VERSION ""

NS_ :

BS_:

BU_: Gateway_Front Gateway_Rear ECU BMS GI_Left GI_Right Dashboard Telemetry IMU LV_SOC Programming

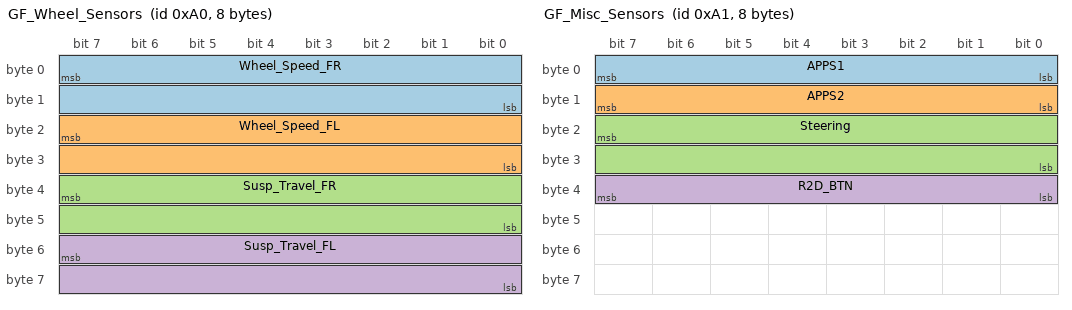
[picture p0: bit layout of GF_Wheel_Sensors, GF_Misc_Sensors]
BO_ 160 GF_Wheel_Sensors: 8 Gateway_Front
 SG_ Wheel_Speed_FR : 7|16@0+ (1.0,0) [0.0|8000.0] "rpm" Telemetry,GI_Left,GI_Right
 SG_ Wheel_Speed_FL : 23|16@0+ (1.0,0) [0.0|8000.0] "rpm" Telemetry,GI_Left,GI_Right
 SG_ Susp_Travel_FR : 39|16@0+ (0.001,0) [0.0|65.535] "mm" Telemetry,GI_Left,GI_Right
 SG_ Susp_Travel_FL : 55|16@0+ (0.001,0) [0.0|65.535] "mm" Telemetry,GI_Left,GI_Right
BO_ 161 GF_Misc_Sensors: 8 Gateway_Front
 SG_ APPS1 : 7|8@0+ (1.0,0) [0.0|100.0] "%" Telemetry,GI_Left,GI_Right,ECU
 SG_ APPS2 : 15|8@0+ (1.0,0) [0.0|100.0] "%" Telemetry,GI_Left,GI_Right,ECU
 SG_ Steering : 23|16@0- (0.01,0) [-290.0|290.0] "deg" Telemetry,GI_Left,GI_Right,ECU
 SG_ R2D_BTN : 39|8@0+ (1.0,0) [0.0|1.0] "bool" Telemetry,GI_Left,GI_Right,ECU
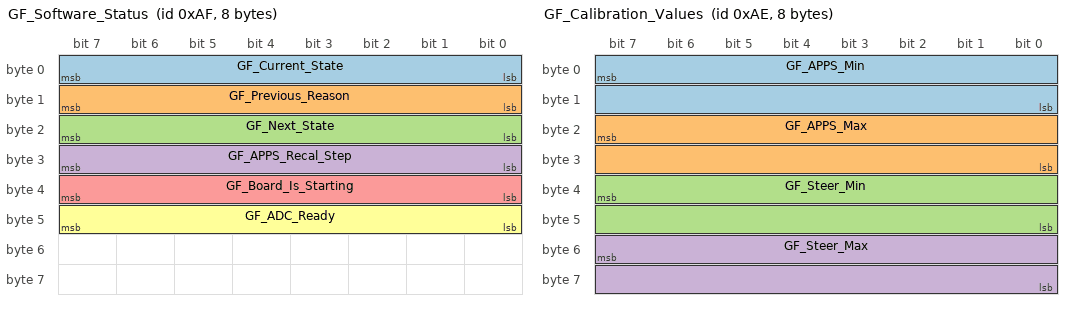
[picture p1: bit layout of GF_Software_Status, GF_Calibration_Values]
BO_ 175 GF_Software_Status: 8 Gateway_Front
 SG_ GF_Current_State : 7|8@0+ (1.0,0) [0.0|255.0] "hex" Telemetry
 SG_ GF_Previous_Reason : 15|8@0+ (1.0,0) [0.0|255.0] "hex" Telemetry
 SG_ GF_Next_State : 23|8@0+ (1.0,0) [0.0|255.0] "hex" Telemetry
 SG_ GF_APPS_Recal_Step : 31|8@0+ (1.0,0) [0.0|3.0] "hex" Telemetry
 SG_ GF_Board_Is_Starting : 39|8@0+ (1.0,0) [0.0|1.0] "bool" Telemetry
 SG_ GF_ADC_Ready : 47|8@0+ (1.0,0) [0.0|1.0] "bool" Telemetry
BO_ 174 GF_Calibration_Values: 8 Gateway_Front
 SG_ GF_APPS_Min : 7|16@0+ (1.0,0) [0.0|65535.0] "dec" Telemetry,Dashboard
 SG_ GF_APPS_Max : 23|16@0+ (1.0,0) [0.0|65535.0] "dec" Telemetry,Dashboard
 SG_ GF_Steer_Min : 39|16@0+ (1.0,0) [0.0|65535.0] "dec" Telemetry,Dashboard
 SG_ GF_Steer_Max : 55|16@0+ (1.0,0) [0.0|65535.0] "dec" Telemetry,Dashboard

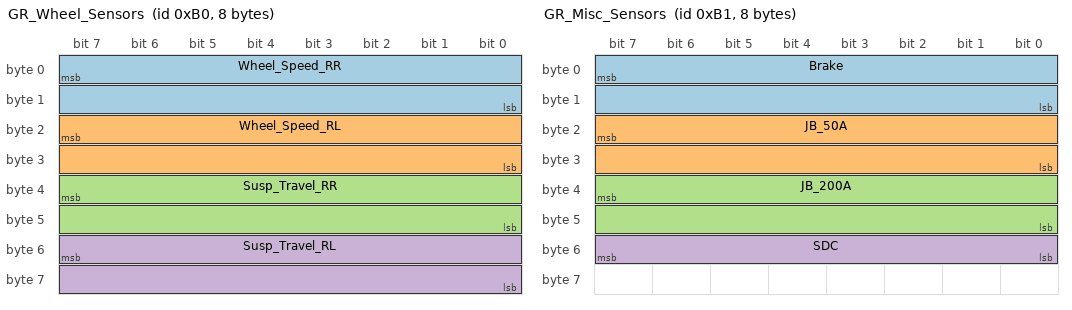
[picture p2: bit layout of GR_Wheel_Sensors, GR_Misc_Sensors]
BO_ 176 GR_Wheel_Sensors: 8 Gateway_Rear
 SG_ Wheel_Speed_RR : 7|16@0+ (1.0,0) [0.0|8000.0] "rpm" Telemetry,GIs
 SG_ Wheel_Speed_RL : 23|16@0+ (1.0,0) [0.0|8000.0] "rpm" Telemetry,GIs
 SG_ Susp_Travel_RR : 39|16@0+ (0.001,0) [0.0|65.535] "mm" Telemetry,GIs
 SG_ Susp_Travel_RL : 55|16@0+ (0.001,0) [0.0|65.535] "mm" Telemetry,GIs
BO_ 177 GR_Misc_Sensors: 8 Gateway_Rear
 SG_ Brake : 7|16@0+ (0.01,0) [0.0|100.0] "bar" Telemetry,GI_Left,GI_Right,ECU
 SG_ JB_50A : 23|16@0- (0.01,0) [-70.0|70.0] "A" Telemetry,GI_Left,GI_Right,ECU
 SG_ JB_200A : 39|16@0- (0.01,0) [-300.0|300.0] "A" Telemetry,GI_Left,GI_Right,ECU
 SG_ SDC : 55|8@0+ (1.0,0) [0.0|1.0] "Bool" Telemetry,GI_Left,GI_Right,ECU
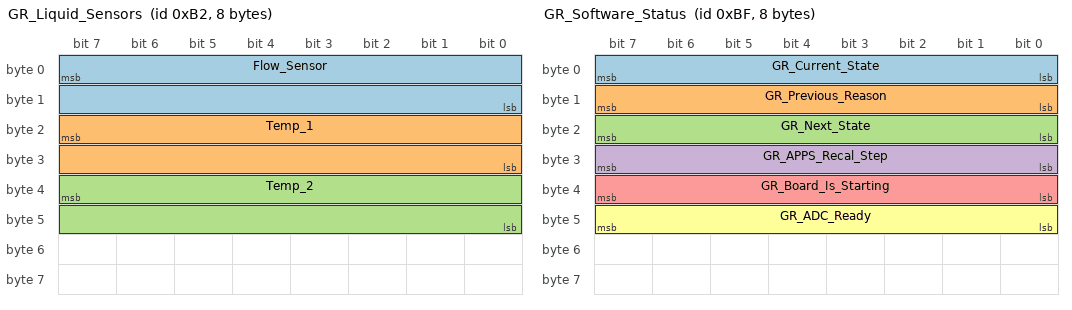
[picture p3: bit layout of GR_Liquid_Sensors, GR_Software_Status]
BO_ 178 GR_Liquid_Sensors: 8 Gateway_Rear
 SG_ Flow_Sensor : 7|16@0+ (1.0,0) [0.0|100.0] "L/m" ECU,Telemetry
 SG_ Temp_1 : 23|16@0- (0.001,0) [-10.0|100.0] "degC" ECU,Telemetry
 SG_ Temp_2 : 39|16@0- (0.001,0) [-10.0|100.0] "degC" ECU,Telemetry
BO_ 191 GR_Software_Status: 8 Gateway_Rear
 SG_ GR_Current_State : 7|8@0+ (1.0,0) [0.0|255.0] "hex" Telemetry
 SG_ GR_Previous_Reason : 15|8@0+ (1.0,0) [0.0|255.0] "hex" Telemetry
 SG_ GR_Next_State : 23|8@0+ (1.0,0) [0.0|255.0] "hex" Telemetry
 SG_ GR_APPS_Recal_Step : 31|8@0+ (1.0,0) [0.0|3.0] "hex" Telemetry
 SG_ GR_Board_Is_Starting : 39|8@0+ (1.0,0) [0.0|1.0] "bool" Telemetry
 SG_ GR_ADC_Ready : 47|8@0+ (1.0,0) [0.0|1.0] "bool" Telemetry

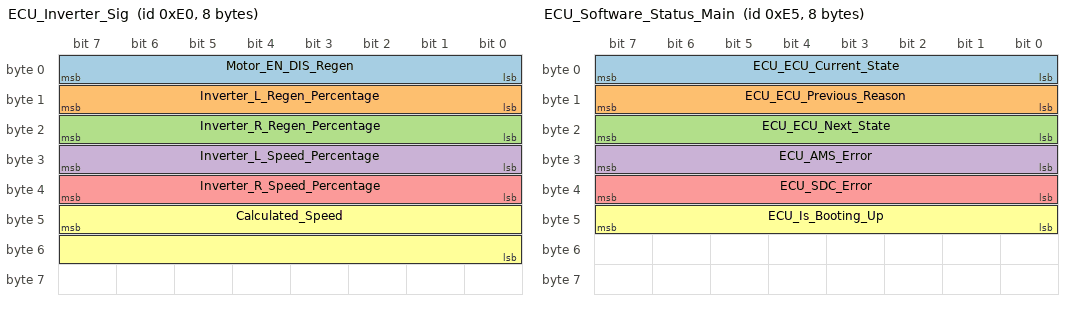
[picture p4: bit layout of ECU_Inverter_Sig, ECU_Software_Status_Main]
BO_ 224 ECU_Inverter_Sig: 8 ECU
 SG_ Motor_EN_DIS_Regen : 7|8@0+ (1.0,0) [0.0|2.0] "enum" Telemetry,GI_Left,GI_Right
 SG_ Inverter_L_Regen_Percentage : 15|8@0+ (1.0,0) [0.0|100.0] "%" Telemetry,GI_Left,GI_Right
 SG_ Inverter_R_Regen_Percentage : 23|8@0+ (1.0,0) [0.0|100.0] "%" Telemetry,GI_Left,GI_Right
 SG_ Inverter_L_Speed_Percentage : 31|8@0+ (1.0,0) [0.0|100.0] "%" Telemetry,GI_Left,GI_Right
 SG_ Inverter_R_Speed_Percentage : 39|8@0+ (1.0,0) [0.0|100.0] "%" Telemetry,GI_Left,GI_Right
 SG_ Calculated_Speed : 47|16@0+ (0.01,0) [0.0|200.0] "km/h" Telemetry,GI_Left,GI_Right
BO_ 179 ECU_Rear_NMOS: 8 ECU
 SG_ R2D_Buzzer_On_Off : 7|8@0+ (1.0,0) [0.0|1.0] "bool" Telemetry,Gateway_Rear
BO_ 162 ECU_Front_NMOS: 8 ECU
 SG_ R2D_LED_Delay : 7|8@0+ (1.0,0) [0.0|255.0] "Hz" Telemetry,Gateway_Front
BO_ 229 ECU_Software_Status_Main: 8 ECU
 SG_ ECU_ECU_Current_State : 7|8@0+ (1.0,0) [0.0|255.0] "hex" Telemetry
 SG_ ECU_ECU_Previous_Reason : 15|8@0+ (1.0,0) [0.0|255.0] "hex" Telemetry
 SG_ ECU_ECU_Next_State : 23|8@0+ (1.0,0) [0.0|255.0] "hex" Telemetry
 SG_ ECU_AMS_Error : 31|8@0+ (1.0,0) [0.0|1.0] "bool" Telemetry
 SG_ ECU_SDC_Error : 39|8@0+ (1.0,0) [0.0|1.0] "bool" Telemetry
 SG_ ECU_Is_Booting_Up : 47|8@0+ (1.0,0) [0.0|1.0] "bool" Telemetry
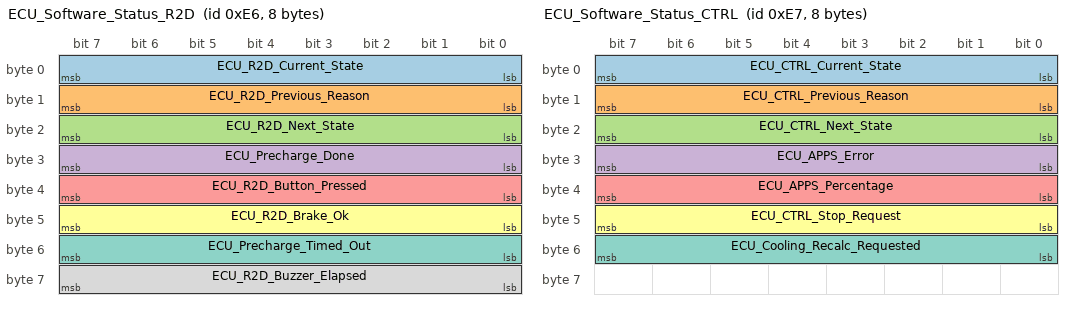
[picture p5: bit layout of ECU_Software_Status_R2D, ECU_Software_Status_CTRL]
BO_ 230 ECU_Software_Status_R2D: 8 ECU
 SG_ ECU_R2D_Current_State : 7|8@0+ (1.0,0) [0.0|255.0] "hex" Telemetry
 SG_ ECU_R2D_Previous_Reason : 15|8@0+ (1.0,0) [0.0|255.0] "hex" Telemetry
 SG_ ECU_R2D_Next_State : 23|8@0+ (1.0,0) [0.0|255.0] "hex" Telemetry
 SG_ ECU_Precharge_Done : 31|8@0+ (1.0,0) [0.0|1.0] "bool" Telemetry
 SG_ ECU_R2D_Button_Pressed : 39|8@0+ (1.0,0) [0.0|1.0] "bool" Telemetry
 SG_ ECU_R2D_Brake_Ok : 47|8@0+ (1.0,0) [0.0|1.0] "bool" Telemetry
 SG_ ECU_Precharge_Timed_Out : 55|8@0+ (1.0,0) [0.0|1.0] "bool" Telemetry
 SG_ ECU_R2D_Buzzer_Elapsed : 63|8@0+ (1.0,0) [0.0|1.0] "bool" Telemetry
BO_ 231 ECU_Software_Status_CTRL: 8 ECU
 SG_ ECU_CTRL_Current_State : 7|8@0+ (1.0,0) [0.0|255.0] "hex" Telemetry
 SG_ ECU_CTRL_Previous_Reason : 15|8@0+ (1.0,0) [0.0|255.0] "hex" Telemetry
 SG_ ECU_CTRL_Next_State : 23|8@0+ (1.0,0) [0.0|255.0] "hex" Telemetry
 SG_ ECU_APPS_Error : 31|8@0+ (1.0,0) [0.0|1.0] "bool" Telemetry
 SG_ ECU_APPS_Percentage : 39|8@0+ (1.0,0) [0.0|1.0] "bool" Telemetry
 SG_ ECU_CTRL_Stop_Request : 47|8@0+ (1.0,0) [0.0|1.0] "bool" Telemetry
 SG_ ECU_Cooling_Recalc_Requested : 55|8@0+ (1.0,0) [0.0|1.0] "bool" Telemetry
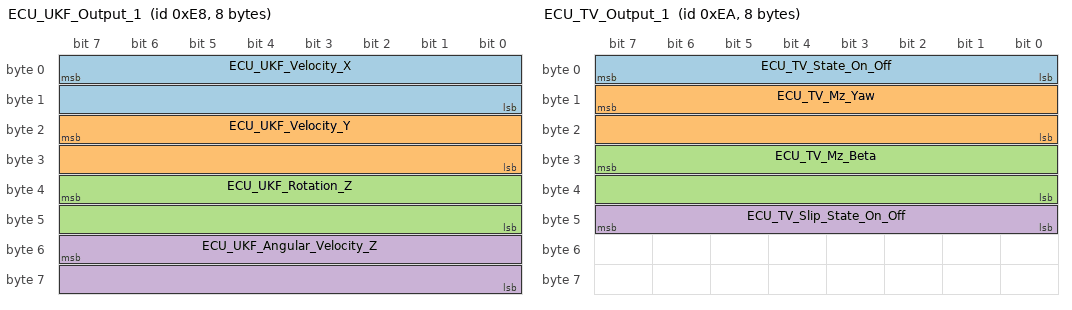
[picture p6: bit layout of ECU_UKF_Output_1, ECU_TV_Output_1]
BO_ 232 ECU_UKF_Output_1: 8 ECU
 SG_ ECU_UKF_Velocity_X : 7|16@0- (0.01,0) [0.0|200.0] "km/h" Telemetry
 SG_ ECU_UKF_Velocity_Y : 23|16@0- (0.001,0) [-30.0|30.0] "m/s" Telemetry
 SG_ ECU_UKF_Rotation_Z : 39|16@0- (0.01,0) [0.0|360.0] "rad" Telemetry
 SG_ ECU_UKF_Angular_Velocity_Z : 55|16@0- (0.01,0) [0.0|360.0] "rad" Telemetry
BO_ 233 ECU_UKF_Output_2: 8 ECU
 SG_ ECU_UKF_Accel_X : 7|16@0- (0.01,0) [0.0|50.0] "m/s^2" Telemetry
 SG_ ECU_UKF_Accel_Y : 23|16@0- (0.01,0) [0.0|50.0] "m/s^2" Telemetry
BO_ 234 ECU_TV_Output_1: 8 ECU
 SG_ ECU_TV_State_On_Off : 7|8@0+ (1.0,0) [0.0|1.0] "number" Telemetry
 SG_ ECU_TV_Mz_Yaw : 15|16@0+ (1.0,0) [0.0|2500.0] "number" Telemetry
 SG_ ECU_TV_Mz_Beta : 31|16@0+ (1.0,0) [0.0|2500.0] "number" Telemetry
 SG_ ECU_TV_Slip_State_On_Off : 47|8@0+ (1.0,0) [0.0|1.0] "number" Telemetry
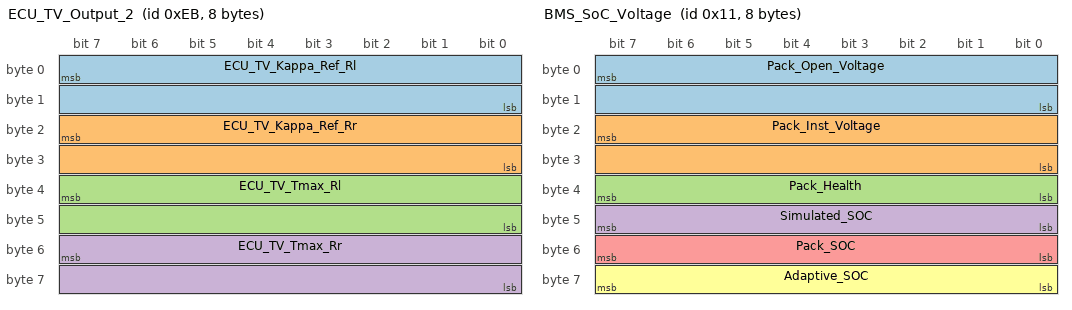
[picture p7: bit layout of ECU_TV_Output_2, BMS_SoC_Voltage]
BO_ 235 ECU_TV_Output_2: 8 ECU
 SG_ ECU_TV_Kappa_Ref_Rl : 7|16@0+ (0.001,0) [0.0|1.0] "number" Telemetry
 SG_ ECU_TV_Kappa_Ref_Rr : 23|16@0+ (0.001,0) [0.0|1.0] "number" Telemetry
 SG_ ECU_TV_Tmax_Rl : 39|16@0+ (0.1,0) [0.0|100.0] "number" Telemetry
 SG_ ECU_TV_Tmax_Rr : 55|16@0+ (0.1,0) [0.0|100.0] "number" Telemetry

BO_ 16 BMS_Errors_Temps: 8 BMS
 SG_ Internal_Temperature : 7|8@0- (1.0,0) [-10.0|100.0] "Celsius" Telemetry,ECU,Dashboard
 SG_ DTC_P0AFA_Low_Cell_Voltage_Fault : 8|1@1+ (1.0,0) [0.0|1.0] "Bool" Telemetry,ECU,Dashboard
 SG_ DTC_P0A04_Cell_Open_Wiring_Fault : 9|1@1+ (1.0,0) [0.0|1.0] "Bool" Telemetry,ECU,Dashboard
 SG_ DTC_P0A0F_Cell_Bank_Fault : 10|1@1+ (1.0,0) [0.0|1.0] "Bool" Telemetry,ECU,Dashboard
 SG_ DTC_U0100_CAN_Communication_Fault : 11|1@1+ (1.0,0) [0.0|1.0] "Bool" Telemetry,ECU,Dashboard
 SG_ DTC_P0A10_Pack_Too_Hot_Fault : 12|1@1+ (1.0,0) [0.0|1.0] "Bool" Telemetry,ECU,Dashboard
 SG_ DTC_P0A0B_Internal_Logic_Fault : 13|1@1+ (1.0,0) [0.0|1.0] "Bool" Telemetry,ECU,Dashboard
 SG_ DTC_P0A12_Cell_Balancing_Stuck_Off_Fault : 14|1@1+ (1.0,0) [0.0|1.0] "Bool" Telemetry,ECU,Dashboard
 SG_ DTC_P0A0E_Lowest_Cell_Voltage_Too_Low_Fault : 15|1@1+ (1.0,0) [0.0|1.0] "Bool" Telemetry,ECU,Dashboard
 SG_ MultiPurpose_Output_3 : 16|1@1+ (1.0,0) [0.0|1.0] "Bool" Telemetry,ECU,Dashboard
 SG_ MultiPurpose_Enable : 17|1@1+ (1.0,0) [0.0|1.0] "Bool" Telemetry,ECU,Dashboard
 SG_ MultiPurpose_Output_4 : 18|1@1+ (1.0,0) [0.0|1.0] "Bool" Telemetry,ECU,Dashboard
 SG_ Balancing_Active : 19|1@1+ (1.0,0) [0.0|1.0] "Bool" Telemetry,ECU,Dashboard
 SG_ Charge_Power_Signal : 20|1@1+ (1.0,0) [0.0|1.0] "Bool" Telemetry,ECU,Dashboard
 SG_ Charge_Mode_Active_CAN : 21|1@1+ (1.0,0) [0.0|1.0] "Bool" Telemetry,ECU,Dashboard
 SG_ Voltage_Failsafe : 22|1@1+ (1.0,0) [0.0|1.0] "Bool" Telemetry,ECU,Dashboard
 SG_ Current_Failsafe : 23|1@1+ (1.0,0) [0.0|1.0] "Bool" Telemetry,ECU,Dashboard
 SG_ DTC_P0A0C_Highest_Cell_Voltage_Too_High_Fault : 24|1@1+ (1.0,0) [0.0|1.0] "Bool" Telemetry,ECU,Dashboard
 SG_ DTC_P0A9C_Thermistor_Fault : 25|1@1+ (1.0,0) [0.0|1.0] "Bool" Telemetry,ECU,Dashboard
 SG_ DTC_P0AC0_Current_Sensor_Fault : 26|1@1+ (1.0,0) [0.0|1.0] "Bool" Telemetry,ECU,Dashboard
 SG_ DTC_P0A04_Cell_Open_Wiring_Fault_1 : 27|1@1+ (1.0,0) [0.0|1.0] "Bool" Telemetry,ECU,Dashboard
 SG_ DTC_P0A80_Weak_Cell_Fault : 28|1@1+ (1.0,0) [0.0|1.0] "Bool" Telemetry,ECU,Dashboard
 SG_ MultiPurpose_Output_2 : 29|1@1+ (1.0,0) [0.0|1.0] "Bool" Telemetry,ECU,Dashboard
 SG_ Low_Temperature : 39|8@0- (1.0,0) [-10.0|80.0] "Celsius" Telemetry,ECU,Dashboard
 SG_ High_Temperature : 47|8@0- (1.0,0) [-10.0|80.0] "Celsius" Telemetry,ECU,Dashboard
 SG_ High_Thermistor_ID : 55|8@0+ (1.0,0) [0.0|255.0] "ID" Telemetry,ECU,Dashboard
 SG_ Low_Thermistor_ID : 63|8@0+ (1.0,0) [0.0|255.0] "ID" Telemetry,ECU,Dashboard
BO_ 17 BMS_SoC_Voltage: 8 BMS
 SG_ Pack_Open_Voltage : 7|16@0+ (0.1,0) [0.0|650.0] "Volts" Telemetry,ECU,Dashboard
 SG_ Pack_Inst_Voltage : 23|16@0+ (0.1,0) [0.0|650.0] "Volts" Telemetry,ECU,Dashboard
 SG_ Pack_Health : 39|8@0+ (1.0,0) [0.0|100.0] "Percent" Telemetry,ECU,Dashboard
 SG_ Simulated_SOC : 47|8@0+ (0.5,0) [0.0|100.0] "Percent" Telemetry,ECU,Dashboard
 SG_ Pack_SOC : 55|8@0+ (0.5,0) [0.0|100.0] "Percent" Telemetry,ECU,Dashboard
 SG_ Adaptive_SOC : 63|8@0+ (0.5,0) [0.0|100.0] "Percent" Telemetry,ECU,Dashboard
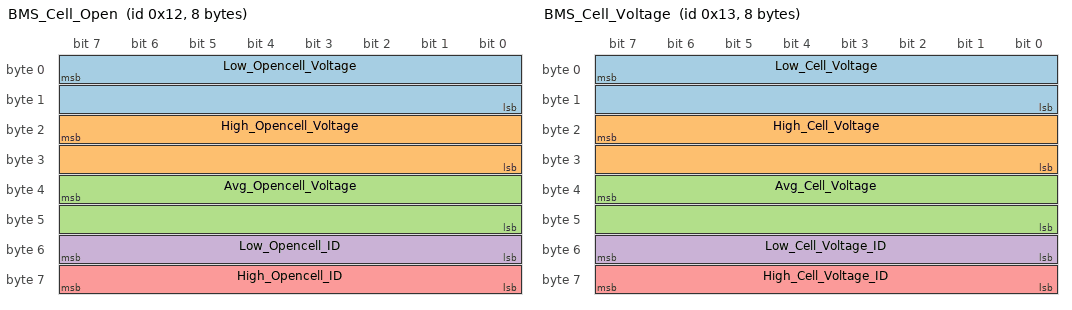
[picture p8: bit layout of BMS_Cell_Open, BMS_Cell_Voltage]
BO_ 18 BMS_Cell_Open: 8 BMS
 SG_ Low_Opencell_Voltage : 7|16@0+ (0.0001,0) [0.0|5.0] "Volts" Telemetry
 SG_ High_Opencell_Voltage : 23|16@0+ (0.0001,0) [0.0|5.0] "Volts" Telemetry
 SG_ Avg_Opencell_Voltage : 39|16@0+ (0.0001,0) [0.0|5.0] "Volts" Telemetry
 SG_ Low_Opencell_ID : 55|8@0+ (1.0,0) [0.0|255.0] "ID" Telemetry
 SG_ High_Opencell_ID : 63|8@0+ (1.0,0) [0.0|255.0] "ID" Telemetry
BO_ 19 BMS_Cell_Voltage: 8 BMS
 SG_ Low_Cell_Voltage : 7|16@0+ (0.0001,0) [0.0|5.0] "Volts" Telemetry
 SG_ High_Cell_Voltage : 23|16@0+ (0.0001,0) [0.0|5.0] "Volts" Telemetry
 SG_ Avg_Cell_Voltage : 39|16@0+ (0.0001,0) [0.0|5.0] "Volts" Telemetry
 SG_ Low_Cell_Voltage_ID : 55|8@0+ (1.0,0) [0.0|255.0] "ID" Telemetry
 SG_ High_Cell_Voltage_ID : 63|8@0+ (1.0,0) [0.0|255.0] "ID" Telemetry
BO_ 20 BMS_Cell_Resistance: 8 BMS
 SG_ Low_Cell_Resistance : 7|16@0+ (0.01,0) [0.0|100.0] "mOhm" Telemetry
 SG_ High_Cell_Resistance : 23|16@0+ (0.01,0) [0.0|100.0] "mOhm" Telemetry
 SG_ Avg_Cell_Resistance : 39|16@0+ (0.01,0) [0.0|100.0] "mOhm" Telemetry
 SG_ High_Intres_ID : 15|8@0+ (1.0,0) [0.0|255.0] "ID" Telemetry
 SG_ Low_Intres_ID : 23|8@0+ (1.0,0) [0.0|255.0] "ID" Telemetry
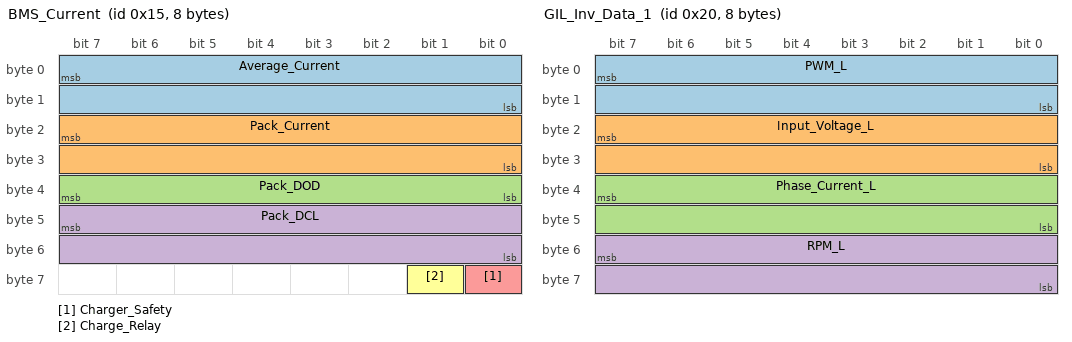
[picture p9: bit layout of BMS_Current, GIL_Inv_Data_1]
BO_ 21 BMS_Current: 8 BMS
 SG_ Average_Current : 7|16@0- (0.1,0) [-500.0|500.0] "Amps" Telemetry,Dashboard
 SG_ Pack_Current : 23|16@0- (0.1,0) [-500.0|500.0] "Amps" Telemetry,Dashboard
 SG_ Pack_DOD : 39|8@0+ (0.5,0) [0.0|100.0] "Percent" Telemetry,Dashboard
 SG_ Pack_DCL : 47|16@0+ (1.0,0) [0.0|500.0] "Amps" Telemetry,Dashboard
 SG_ Charger_Safety : 56|1@1+ (1.0,0) [0.0|1.0] "Bool" Telemetry,Dashboard
 SG_ Charge_Relay : 57|1@1+ (1.0,0) [0.0|1.0] "Bool" Telemetry,Dashboard

BO_ 32 GIL_Inv_Data_1: 8 GI_Left
 SG_ PWM_L : 7|16@0+ (1.0,0) [0.0|1000.0] "raw" Telemetry
 SG_ Input_Voltage_L : 23|16@0+ (0.1,0) [0.0|410.0] "V" Telemetry
 SG_ Phase_Current_L : 39|16@0+ (0.1,0) [0.0|511.0] "A" Telemetry
 SG_ RPM_L : 55|16@0+ (1.0,0) [0.0|65535.0] "rpm" Telemetry
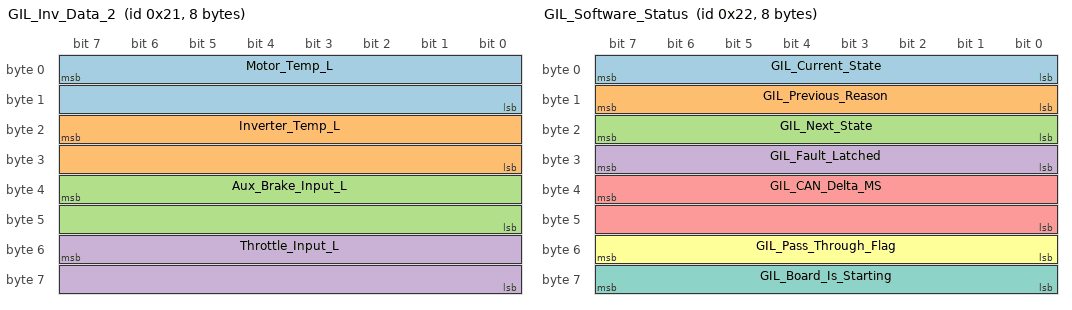
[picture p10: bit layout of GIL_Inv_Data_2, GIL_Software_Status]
BO_ 33 GIL_Inv_Data_2: 8 GI_Left
 SG_ Motor_Temp_L : 7|16@0- (1.0,0) [-100.0|155.0] "degC" ECU,Telemetry
 SG_ Inverter_Temp_L : 23|16@0- (1.0,0) [-100.0|155.0] "degC" ECU,Telemetry
 SG_ Aux_Brake_Input_L : 39|16@0+ (0.001,0) [0.0|5.0] "V" ECU,Telemetry
 SG_ Throttle_Input_L : 55|16@0+ (0.001,0) [0.0|5.0] "V" ECU,Telemetry
BO_ 34 GIL_Software_Status: 8 GI_Left
 SG_ GIL_Current_State : 7|8@0+ (1.0,0) [0.0|255.0] "hex" Telemetry
 SG_ GIL_Previous_Reason : 15|8@0+ (1.0,0) [0.0|255.0] "hex" Telemetry
 SG_ GIL_Next_State : 23|8@0+ (1.0,0) [0.0|255.0] "hex" Telemetry
 SG_ GIL_Fault_Latched : 31|8@0+ (1.0,0) [0.0|1.0] "bool" Telemetry
 SG_ GIL_CAN_Delta_MS : 39|16@0+ (1.0,0) [0.0|65535.0] "hex" Telemetry
 SG_ GIL_Pass_Through_Flag : 55|8@0+ (1.0,0) [0.0|1.0] "bool" Telemetry
 SG_ GIL_Board_Is_Starting : 63|8@0+ (1.0,0) [0.0|1.0] "bool" Telemetry

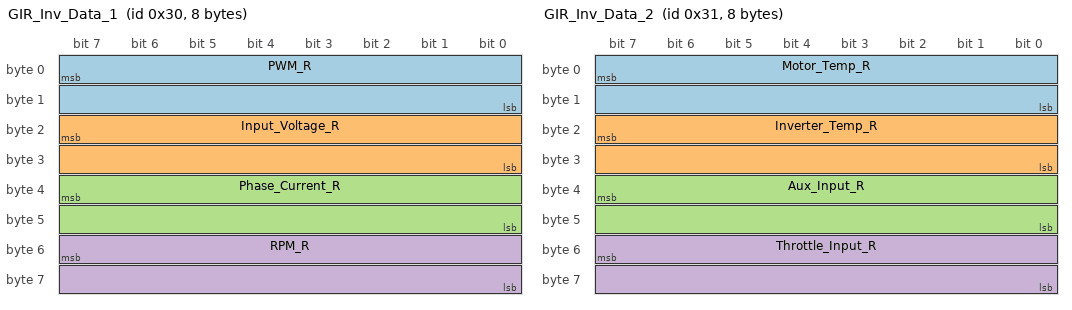
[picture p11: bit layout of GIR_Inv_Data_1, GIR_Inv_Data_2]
BO_ 48 GIR_Inv_Data_1: 8 GI_Right
 SG_ PWM_R : 7|16@0+ (1.0,0) [0.0|1000.0] "raw" Telemetry
 SG_ Input_Voltage_R : 23|16@0+ (0.1,0) [0.0|410.0] "V" Telemetry
 SG_ Phase_Current_R : 39|16@0+ (0.1,0) [0.0|511.0] "A" Telemetry
 SG_ RPM_R : 55|16@0+ (1.0,0) [0.0|65535.0] "rpm" Telemetry
BO_ 49 GIR_Inv_Data_2: 8 GI_Right
 SG_ Motor_Temp_R : 7|16@0- (1.0,0) [-100.0|155.0] "degC" ECU,Telemetry
 SG_ Inverter_Temp_R : 23|16@0- (1.0,0) [-100.0|155.0] "degC" ECU,Telemetry
 SG_ Aux_Input_R : 39|16@0+ (0.001,0) [0.0|5.0] "V" ECU,Telemetry
 SG_ Throttle_Input_R : 55|16@0+ (0.001,0) [0.0|5.0] "V" ECU,Telemetry
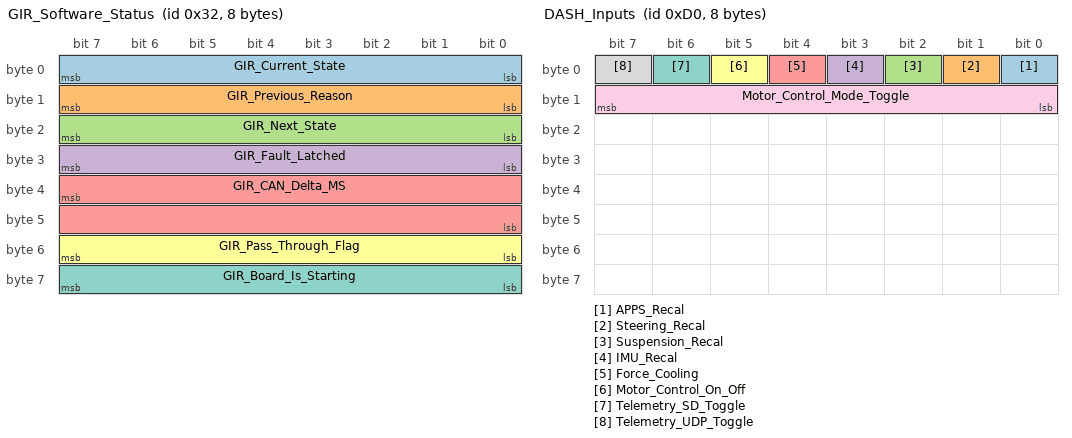
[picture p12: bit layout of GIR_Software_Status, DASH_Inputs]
BO_ 50 GIR_Software_Status: 8 GI_Right
 SG_ GIR_Current_State : 7|8@0+ (1.0,0) [0.0|255.0] "hex" Telemetry
 SG_ GIR_Previous_Reason : 15|8@0+ (1.0,0) [0.0|255.0] "hex" Telemetry
 SG_ GIR_Next_State : 23|8@0+ (1.0,0) [0.0|255.0] "hex" Telemetry
 SG_ GIR_Fault_Latched : 31|8@0+ (1.0,0) [0.0|1.0] "bool" Telemetry
 SG_ GIR_CAN_Delta_MS : 39|16@0+ (1.0,0) [0.0|65535.0] "hex" Telemetry
 SG_ GIR_Pass_Through_Flag : 55|8@0+ (1.0,0) [0.0|1.0] "bool" Telemetry
 SG_ GIR_Board_Is_Starting : 63|8@0+ (1.0,0) [0.0|1.0] "bool" Telemetry

BO_ 208 DASH_Inputs: 8 Dashboard
 SG_ APPS_Recal : 0|1@1+ (1.0,0) [0.0|1.0] "bool" Telemetry,ECU
 SG_ Steering_Recal : 1|1@1+ (1.0,0) [0.0|1.0] "bool" Telemetry,ECU
 SG_ Suspension_Recal : 2|1@1+ (1.0,0) [0.0|1.0] "bool" Telemetry,ECU
 SG_ IMU_Recal : 3|1@1+ (1.0,0) [0.0|1.0] "bool" Telemetry,ECU
 SG_ Force_Cooling : 4|1@1+ (1.0,0) [0.0|1.0] "bool" Telemetry,ECU
 SG_ Motor_Control_On_Off : 5|1@1+ (1.0,0) [0.0|1.0] "enum" Telemetry,ECU
 SG_ Telemetry_SD_Toggle : 6|1@1+ (1.0,0) [0.0|1.0] "bool" Telemetry,ECU
 SG_ Telemetry_UDP_Toggle : 7|1@1+ (1.0,0) [0.0|1.0] "bool" Telemetry,ECU
 SG_ Motor_Control_Mode_Toggle : 15|8@0+ (1.0,0) [0.0|255.0] "enum" Telemetry,ECU
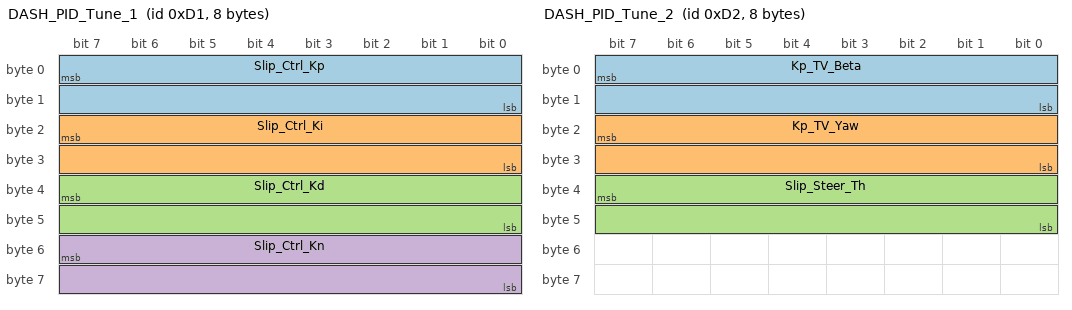
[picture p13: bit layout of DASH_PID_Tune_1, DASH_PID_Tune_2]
BO_ 209 DASH_PID_Tune_1: 8 Dashboard
 SG_ Slip_Ctrl_Kp : 7|16@0+ (1.0,0) [0.0|65535.0] "unit" Telemetry,ECU
 SG_ Slip_Ctrl_Ki : 23|16@0+ (1.0,0) [0.0|65535.0] "unit" Telemetry,ECU
 SG_ Slip_Ctrl_Kd : 39|16@0+ (0.01,0) [0.0|655.35] "unit" Telemetry,ECU
 SG_ Slip_Ctrl_Kn : 55|16@0+ (1.0,0) [0.0|100.0] "unit" Telemetry,ECU
BO_ 210 DASH_PID_Tune_2: 8 Dashboard
 SG_ Kp_TV_Beta : 7|16@0+ (1.0,0) [0.0|1000.0] "unit" Telemetry,ECU
 SG_ Kp_TV_Yaw : 23|16@0+ (1.0,0) [0.0|1500.0] "unit" Telemetry,ECU
 SG_ Slip_Steer_Th : 39|16@0+ (1.0,0) [0.0|255.0] "deg" Telemetry,ECU

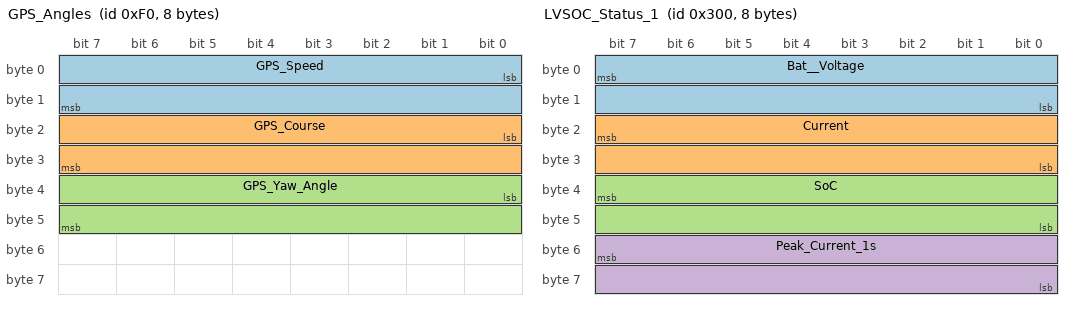
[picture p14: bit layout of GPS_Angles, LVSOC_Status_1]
BO_ 240 GPS_Angles: 8 Telemetry
 SG_ GPS_Speed : 0|16@1- (0.01,0) [0.0|327.67] "m/s" ECU
 SG_ GPS_Course : 16|16@1- (0.0001,0) [-3.15|3.15] "rad" ECU
 SG_ GPS_Yaw_Angle : 32|16@1- (0.0001,0) [-3.15|3.15] "rad" ECU

BO_ 80 IMU_Data: 8 IMU
 SG_ IMU_Header : 7|8@0+ (1.0,0) [0.0|255.0] "const_0x55" Telemetry,ECU
 SG_ IMU_Msg_Type M : 15|8@0+ (1.0,0) [0.0|255.0] "hex" Telemetry,ECU
 SG_ Accel_X m81 : 23|16@0- (0.00048828125,0) [-16.0|16.0] "g" Telemetry,ECU
 SG_ Accel_Y m81 : 39|16@0- (0.00048828125,0) [-16.0|16.0] "g" Telemetry,ECU
 SG_ Accel_Z m81 : 55|16@0- (0.00048828125,0) [-16.0|16.0] "g" Telemetry,ECU
 SG_ Gyro_X m82 : 23|16@0- (0.06103515625,0) [-2000.0|200.0] "deg/s" Telemetry,ECU
 SG_ Gyro_Y m82 : 39|16@0- (0.06103515625,0) [-2000.0|200.0] "deg/s" Telemetry,ECU
 SG_ Gyro_Z m82 : 55|16@0- (0.06103515625,0) [-2000.0|200.0] "deg/s" Telemetry,ECU
 SG_ Angle_Roll m83 : 23|16@0- (0.0054931640625,0) [-180.0|180.0] "deg" Telemetry,ECU
 SG_ Angle_Pitch m83 : 39|16@0- (0.0054931640625,0) [-180.0|180.0] "deg" Telemetry,ECU
 SG_ Angle_Yaw m83 : 55|16@0- (0.0054931640625,0) [-180.0|180.0] "deg" Telemetry,ECU
BO_ 80 IMU_Recal: 8 IMU
 SG_ Protocol_Header_1 : 7|8@0+ (1.0,0) [0.0|255.0] "const_0xff" IMU
 SG_ Protocol_Header_2 : 15|8@0+ (1.0,0) [0.0|255.0] "const_0xaa" IMU
 SG_ Address M : 23|8@0+ (1.0,0) [0.0|255.0] "hex" IMU
 SG_ KEY_Low m105 : 31|8@0+ (1.0,0) [0.0|255.0] "hex" IMU
 SG_ KEY_High m105 : 39|8@0+ (1.0,0) [0.0|255.0] "hex" IMU
 SG_ CALSW_Low m1 : 31|8@0+ (1.0,0) [0.0|255.0] "hex" IMU
 SG_ CALSW_High m1 : 39|8@0+ (1.0,0) [0.0|255.0] "hex" IMU
 SG_ SAVE_Low m0 : 31|8@0+ (1.0,0) [0.0|255.0] "hex" IMU
 SG_ SAVE_High m0 : 39|8@0+ (1.0,0) [0.0|255.0] "hex" IMU

BO_ 768 LVSOC_Status_1: 8 LV_SOC
 SG_ Bat__Voltage : 7|16@0+ (0.001,0) [0.0|65535.0] "V" Telemetry,Dashboard
 SG_ Current : 23|16@0- (0.01,0) [-327.68|327.67] "A" Telemetry,Dashboard
 SG_ SoC : 39|16@0+ (0.1,0) [0.0|100.0] "%" Telemetry,Dashboard
 SG_ Peak_Current_1s : 55|16@0- (0.01,0) [-327.68|327.67] "A" Telemetry,Dashboard
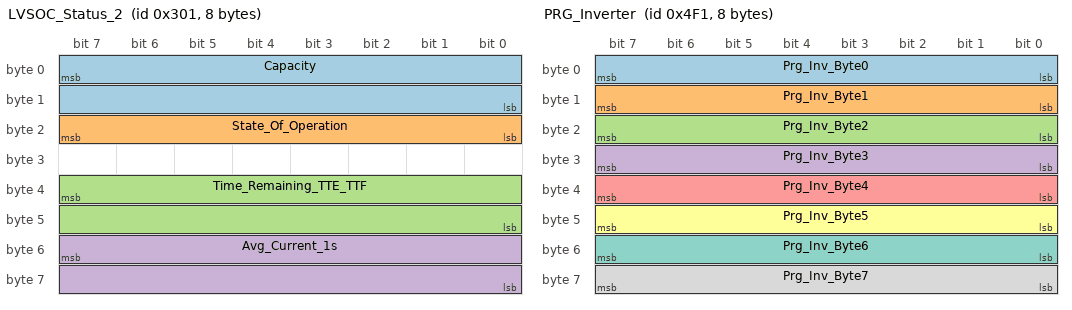
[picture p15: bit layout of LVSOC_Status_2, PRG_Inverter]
BO_ 769 LVSOC_Status_2: 8 LV_SOC
 SG_ Capacity : 7|16@0+ (1.0,0) [0.0|65535.0] "mAh" Telemetry
 SG_ State_Of_Operation : 23|8@0+ (1.0,0) [0.0|255.0] "enum" Telemetry
 SG_ Time_Remaining_TTE_TTF : 39|16@0+ (1.0,0) [0.0|65535.0] "min" Telemetry
 SG_ Avg_Current_1s : 55|16@0- (0.01,0) [-327.68|327.67] "A" Telemetry
BO_ 770 LVSOC_Status_3: 8 LV_SOC
 SG_ OCV : 7|16@0+ (0.001,0) [0.0|65.535] "V" Telemetry

BO_ 1264 PRG_Bootloader: 8 Programming
 SG_ MCU_ID : 7|8@0+ (1.0,0) [0.0|255.0] "id" Gateway_Front,Gateway_Rear,ECU,BMS,GI_Left,GI_Right,Dashboard,Telemetry
BO_ 1265 PRG_Inverter: 8 Programming
 SG_ Prg_Inv_Byte0 : 7|8@0+ (1.0,0) [0.0|255.0] "hex" GI_Left,GI_Right
 SG_ Prg_Inv_Byte1 : 15|8@0+ (1.0,0) [0.0|255.0] "hex" GI_Left,GI_Right
 SG_ Prg_Inv_Byte2 : 23|8@0+ (1.0,0) [0.0|255.0] "hex" GI_Left,GI_Right
 SG_ Prg_Inv_Byte3 : 31|8@0+ (1.0,0) [0.0|255.0] "hex" GI_Left,GI_Right
 SG_ Prg_Inv_Byte4 : 39|8@0+ (1.0,0) [0.0|255.0] "hex" GI_Left,GI_Right
 SG_ Prg_Inv_Byte5 : 47|8@0+ (1.0,0) [0.0|255.0] "hex" GI_Left,GI_Right
 SG_ Prg_Inv_Byte6 : 55|8@0+ (1.0,0) [0.0|255.0] "hex" GI_Left,GI_Right
 SG_ Prg_Inv_Byte7 : 63|8@0+ (1.0,0) [0.0|255.0] "hex" GI_Left,GI_Right

BA_DEF_ BO_  "GenMsgCycleTime" INT 0 65535;
BA_DEF_DEF_  "GenMsgCycleTime" 0;
BA_ "GenMsgCycleTime" BO_ 160 7;
BA_ "GenMsgCycleTime" BO_ 161 7;
BA_ "GenMsgCycleTime" BO_ 176 7;
BA_ "GenMsgCycleTime" BO_ 177 7;
BA_ "GenMsgCycleTime" BO_ 178 200;
BA_ "GenMsgCycleTime" BO_ 224 20;
BA_ "GenMsgCycleTime" BO_ 232 50;
BA_ "GenMsgCycleTime" BO_ 233 50;
BA_ "GenMsgCycleTime" BO_ 234 50;
BA_ "GenMsgCycleTime" BO_ 235 50;
BA_ "GenMsgCycleTime" BO_ 16 23;
BA_ "GenMsgCycleTime" BO_ 17 47;
BA_ "GenMsgCycleTime" BO_ 18 47;
BA_ "GenMsgCycleTime" BO_ 19 47;
BA_ "GenMsgCycleTime" BO_ 20 47;
BA_ "GenMsgCycleTime" BO_ 21 47;
BA_ "GenMsgCycleTime" BO_ 32 20;
BA_ "GenMsgCycleTime" BO_ 33 20;
BA_ "GenMsgCycleTime" BO_ 48 20;
BA_ "GenMsgCycleTime" BO_ 49 20;
BA_ "GenMsgCycleTime" BO_ 240 50;
BA_ "GenMsgCycleTime" BO_ 80 5;
BA_ "GenMsgCycleTime" BO_ 768 1000;
BA_ "GenMsgCycleTime" BO_ 769 1000;
BA_ "GenMsgCycleTime" BO_ 770 1000;
VAL_ 175 GF_Current_State 0 "BOARD_FSM_MODE_INIT" 1 "BOARD_FSM_MODE_IDLE" 2 "BOARD_FSM_MODE_PROCESS_SENSORS" 3 "BOARD_FSM_MODE_OUTPUT_SENSORS" 4 "BOARD_FSM_MODE_BOOTLOADER" 5 "BOARD_FSM_MODE_FAULT" ;
VAL_ 175 GF_Previous_Reason 0 "BOARD_FSM_REASON_NONE" 1 "BOARD_FSM_REASON_INIT_COMPLETE" 2 "BOARD_FSM_REASON_ADC_READY" 3 "BOARD_FSM_REASON_PROCESS_SENSORS_DONE" 4 "BOARD_FSM_REASON_OUTPUT_SENSORS_COMPLETE" 5 "BOARD_FSM_REASON_BOOTLOADER_REQUEST" 6 "BOARD_FSM_REASON_FORCE_FAULT" 7 "BOARD_FSM_REASON_INVALID_EVENT" ;
VAL_ 175 GF_Next_State 0 "BOARD_FSM_MODE_INIT" 1 "BOARD_FSM_MODE_IDLE" 2 "BOARD_FSM_MODE_PROCESS_SENSORS" 3 "BOARD_FSM_MODE_OUTPUT_SENSORS" 4 "BOARD_FSM_MODE_BOOTLOADER" 5 "BOARD_FSM_MODE_FAULT" ;
VAL_ 191 GR_Current_State 0 "BOARD_FSM_MODE_INIT" 1 "BOARD_FSM_MODE_IDLE" 2 "BOARD_FSM_MODE_PROCESS_SENSORS" 3 "BOARD_FSM_MODE_OUTPUT_SENSORS" 4 "BOARD_FSM_MODE_BOOTLOADER" 5 "BOARD_FSM_MODE_FAULT" ;
VAL_ 191 GR_Previous_Reason 0 "BOARD_FSM_REASON_NONE" 1 "BOARD_FSM_REASON_INIT_COMPLETE" 2 "BOARD_FSM_REASON_ADC_READY" 3 "BOARD_FSM_REASON_PROCESS_SENSORS_DONE" 4 "BOARD_FSM_REASON_OUTPUT_SENSORS_COMPLETE" 5 "BOARD_FSM_REASON_BOOTLOADER_REQUEST" 6 "BOARD_FSM_REASON_FORCE_FAULT" 7 "BOARD_FSM_REASON_INVALID_EVENT" ;
VAL_ 191 GR_Next_State 0 "BOARD_FSM_MODE_INIT" 1 "BOARD_FSM_MODE_IDLE" 2 "BOARD_FSM_MODE_PROCESS_SENSORS" 3 "BOARD_FSM_MODE_OUTPUT_SENSORS" 4 "BOARD_FSM_MODE_BOOTLOADER" 5 "BOARD_FSM_MODE_FAULT" ;
VAL_ 229 ECU_ECU_Current_State 0 "SYSTEM_INIT" 1 "SYSTEM_IDLE" 2 "SYSTEM_R2D" 3 "SYSTEM_CONTROL" 4 "SYSTEM_SHUTDOWN" ;
VAL_ 229 ECU_ECU_Previous_Reason 0 "ECU_FSM_REASON_NONE" 1 "ECU_FSM_REASON_REQUEST_IDLE" 2 "ECU_FSM_REASON_REQUEST_R2D" 3 "ECU_FSM_REASON_REQUEST_CONTROL" 4 "ECU_FSM_REASON_REQUEST_SHUTDOWN" 5 "ECU_FSM_REASON_REQUEST_FAULT" 6 "ECU_FSM_REASON_FAULT_CAN_SDC" 7 "ECU_FSM_REASON_FAULT_CAN_AMS" 8 "ECU_FSM_REASON_FAULT_APPS_TIMEOUT" 9 "ECU_FSM_REASON_FAULT_BRAKE_TIMEOUT" 10 "ECU_FSM_REASON_FAULT_SDC_TIMEOUT" 11 "ECU_FSM_REASON_FAULT_PRECHARGE_TIMEOUT" 12 "ECU_FSM_REASON_FAULT_LATCHED" 13 "ECU_FSM_REASON_PRESSED_R2D_BTN_IN_CONTROL" 14 "ECU_FSM_REASON_UNEXPECTED_STATE" ;
VAL_ 229 ECU_ECU_Next_State 0 "SYSTEM_INIT" 1 "SYSTEM_IDLE" 2 "SYSTEM_R2D" 3 "SYSTEM_CONTROL" 4 "SYSTEM_SHUTDOWN" ;
VAL_ 230 ECU_R2D_Current_State 0 "SYSTEM_R2D_FIRST_BTN" 1 "SYSTEM_R2D_PRECH_ONGOING" 2 "SYSTEM_R2D_SECOND_BTN" 3 "SYSTEM_R2D_BUZZING" ;
VAL_ 230 ECU_R2D_Previous_Reason 0 "R2D_FSM_REASON_NONE" 1 "R2D_FSM_REASON_PRECHARGE_DONE" 2 "R2D_FSM_REASON_PRECHARGE_TIMEOUT" 3 "R2D_FSM_REASON_SECOND_BUTTON_BRAKE" 4 "R2D_FSM_REASON_BUZZER_COMPLETE" ;
VAL_ 230 ECU_R2D_Next_State 0 "SYSTEM_R2D_FIRST_BTN" 1 "SYSTEM_R2D_PRECH_ONGOING" 2 "SYSTEM_R2D_SECOND_BTN" 3 "SYSTEM_R2D_BUZZING" ;
VAL_ 231 ECU_CTRL_Current_State 0 "SYSTEM_CONTROL_COOLING" 1 "SYSTEM_CONTROL_MOTORS" 2 "SYSTEM_CONTROL_APPS_VALIDATION" ;
VAL_ 231 ECU_CTRL_Previous_Reason 0 "CONTROL_FSM_REASON_NONE" 1 "CONTROL_FSM_REASON_DRIVER_STOP_REQUEST" 2 "CONTROL_FSM_REASON_APPS_ERROR" 3 "CONTROL_FSM_REASON_APPS_VALID" 4 "CONTROL_FSM_REASON_COOLING_RECYCLE" ;
VAL_ 231 ECU_CTRL_Next_State 0 "SYSTEM_CONTROL_COOLING" 1 "SYSTEM_CONTROL_MOTORS" 2 "SYSTEM_CONTROL_APPS_VALIDATION" ;
VAL_ 34 GIL_Current_State 0 "BOARD_FSM_MODE_INIT" 1 "BOARD_FSM_MODE_READY" 2 "BOARD_FSM_MODE_TORQUE_ACTIVE" 3 "BOARD_FSM_MODE_REGEN_ACTIVE" 4 "BOARD_FSM_MODE_PROGRAMMING" 5 "BOARD_FSM_MODE_BOOTLOADER" 6 "BOARD_FSM_MODE_FAULT" ;
VAL_ 34 GIL_Previous_Reason 0 "BOARD_FSM_REASON_NONE" 1 "BOARD_FSM_REASON_INIT_COMPLETE" 2 "BOARD_FSM_REASON_ECU_DISABLE" 3 "BOARD_FSM_REASON_ECU_ENABLE" 4 "BOARD_FSM_REASON_ECU_REGEN" 5 "BOARD_FSM_REASON_PASS_THROUGH" 6 "BOARD_FSM_REASON_CAN_TIMEOUT" 7 "BOARD_FSM_REASON_INVALID_CMD" 8 "BOARD_FSM_REASON_BOOTLOADER_REQUEST" ;
VAL_ 34 GIL_Next_State 0 "BOARD_FSM_MODE_INIT" 1 "BOARD_FSM_MODE_READY" 2 "BOARD_FSM_MODE_TORQUE_ACTIVE" 3 "BOARD_FSM_MODE_REGEN_ACTIVE" 4 "BOARD_FSM_MODE_PROGRAMMING" 5 "BOARD_FSM_MODE_BOOTLOADER" 6 "BOARD_FSM_MODE_FAULT" ;
VAL_ 50 GIR_Current_State 0 "BOARD_FSM_MODE_INIT" 1 "BOARD_FSM_MODE_READY" 2 "BOARD_FSM_MODE_TORQUE_ACTIVE" 3 "BOARD_FSM_MODE_REGEN_ACTIVE" 4 "BOARD_FSM_MODE_PROGRAMMING" 5 "BOARD_FSM_MODE_BOOTLOADER" 6 "BOARD_FSM_MODE_FAULT" ;
VAL_ 50 GIR_Previous_Reason 0 "BOARD_FSM_REASON_NONE" 1 "BOARD_FSM_REASON_INIT_COMPLETE" 2 "BOARD_FSM_REASON_ECU_DISABLE" 3 "BOARD_FSM_REASON_ECU_ENABLE" 4 "BOARD_FSM_REASON_ECU_REGEN" 5 "BOARD_FSM_REASON_PASS_THROUGH" 6 "BOARD_FSM_REASON_CAN_TIMEOUT" 7 "BOARD_FSM_REASON_INVALID_CMD" 8 "BOARD_FSM_REASON_BOOTLOADER_REQUEST" ;
VAL_ 50 GIR_Next_State 0 "BOARD_FSM_MODE_INIT" 1 "BOARD_FSM_MODE_READY" 2 "BOARD_FSM_MODE_TORQUE_ACTIVE" 3 "BOARD_FSM_MODE_REGEN_ACTIVE" 4 "BOARD_FSM_MODE_PROGRAMMING" 5 "BOARD_FSM_MODE_BOOTLOADER" 6 "BOARD_FSM_MODE_FAULT" ;
VAL_ 208 Motor_Control_On_Off 0 "OFF" 1 "ON" ;
VAL_ 208 Telemetry_SD_Toggle 0 "OFF" 1 "ON" ;
VAL_ 208 Telemetry_UDP_Toggle 0 "OFF" 1 "ON" ;
VAL_ 769 State_Of_Operation 0 "INOP" 1 "NORMAL" 2 "FORCEFUL_RELEARN" 3 "COMMANDED_RELEARN" 4 "RELEARN_WAIT_CHARGE" 5 "RELEARN_WAIT_DISCHARGE" ;
